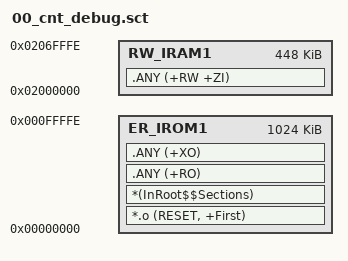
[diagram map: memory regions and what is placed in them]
; *************************************************************
; *** Scatter-Loading Description File generated by uVision ***
; *************************************************************

LR_IROM1 0x00000000 0x000FFFFF  {    ; load region size_region
  ER_IROM1 0x00000000 0x000FFFFF  {  ; load address = execution address
   *.o (RESET, +First)
   *(InRoot$$Sections)
   .ANY (+RO)
   .ANY (+XO)
  }
  RW_IRAM1 0x02000000 0x0006FFFF  {  ; RW data
   .ANY (+RW +ZI)
  }
}

